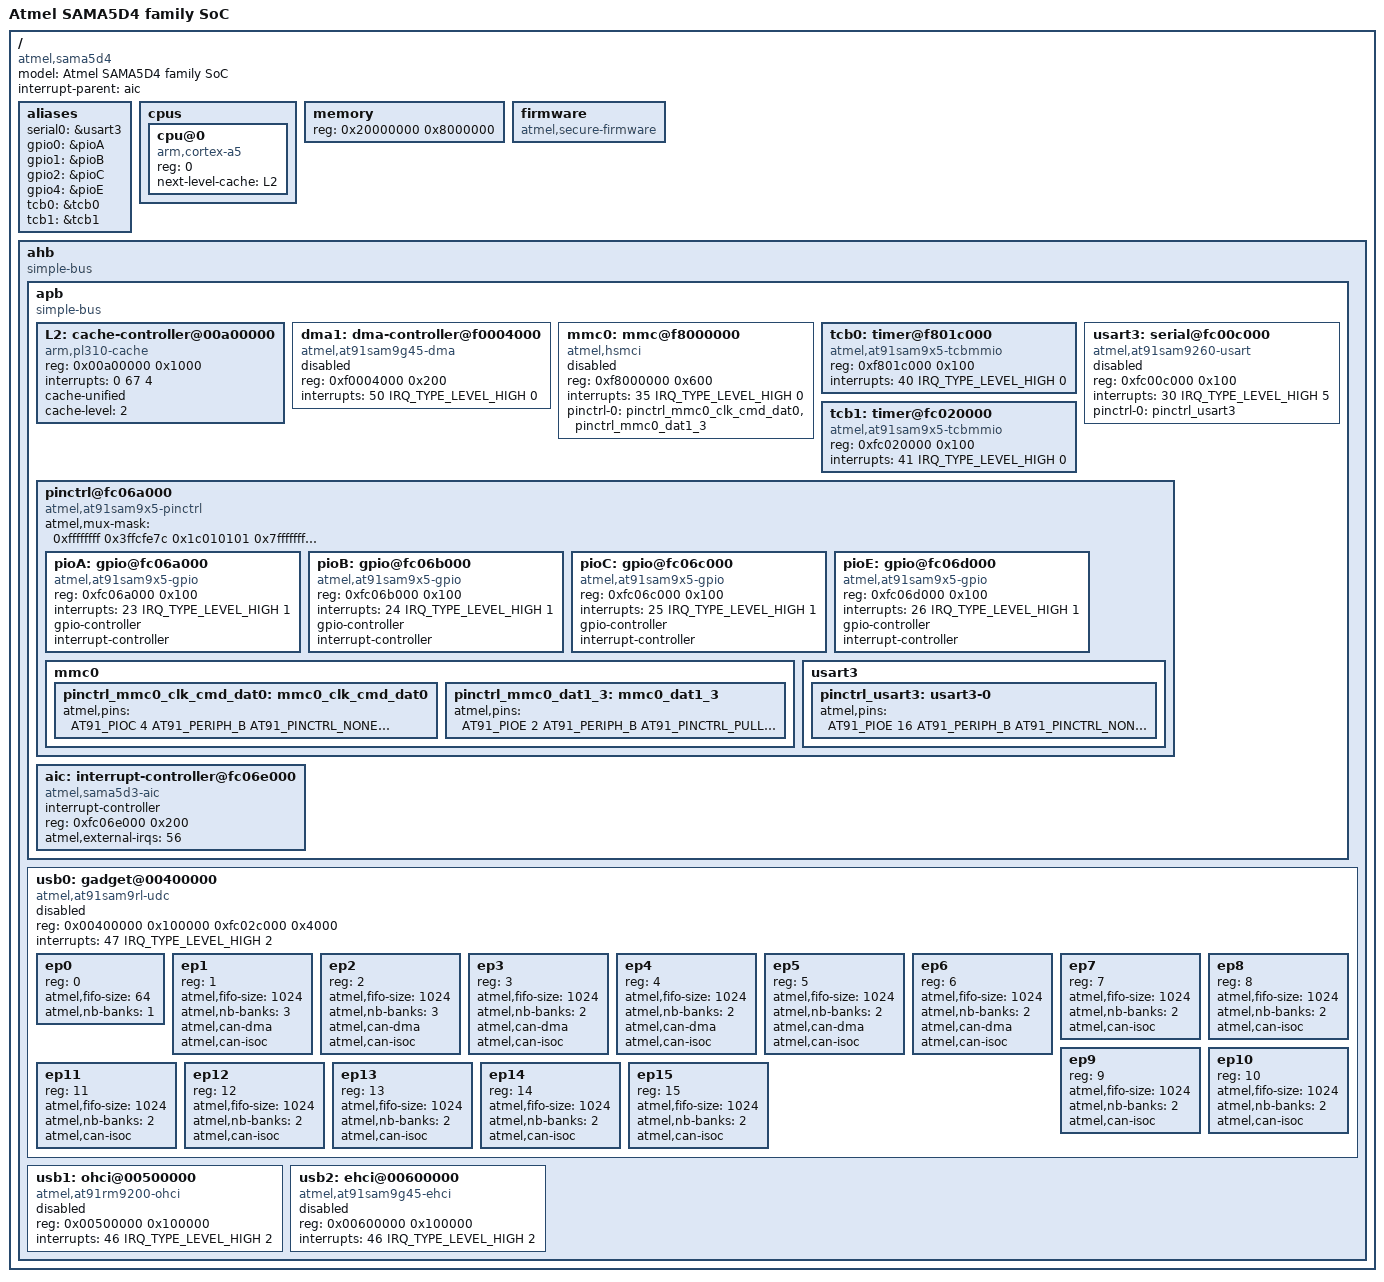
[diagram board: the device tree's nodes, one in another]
/*
 * sama5d4.dtsi - Device Tree Include file for SAMA5D4 family SoC
 *                applies to ISLERO SoC
 *
 *  Copyright (C) 2013 Atmel,
 *                2013 Nicolas Ferre <nicolas.ferre@atmel.com>
 *
 * Licensed under GPLv2 or later.
 */

#include "skeleton.dtsi"
#include <dt-bindings/dma/at91.h>
#include <dt-bindings/pinctrl/at91.h>
#include <dt-bindings/interrupt-controller/irq.h>
#include <dt-bindings/gpio/gpio.h>

/ {
	model = "Atmel SAMA5D4 family SoC";
	compatible = "atmel,sama5d4";
	interrupt-parent = <&aic>;

	aliases {
		serial0 = &usart3;
		gpio0 = &pioA;
		gpio1 = &pioB;
		gpio2 = &pioC;
		gpio4 = &pioE;
		tcb0 = &tcb0;
		tcb1 = &tcb1;
	};
	cpus {
		#address-cells = <1>;
		#size-cells = <0>;

		cpu@0 {
			compatible = "arm,cortex-a5";
			reg = <0>;
			next-level-cache = <&L2>;
		};
	};

	memory {
		reg = <0x20000000 0x8000000>;
	};

	firmware {
		compatible = "atmel,secure-firmware";
	};

	ahb {
		compatible = "simple-bus";
		#address-cells = <1>;
		#size-cells = <1>;
		ranges;

		apb {
			compatible = "simple-bus";
			#address-cells = <1>;
			#size-cells = <1>;
			ranges;

			L2: cache-controller@00a00000 {
				compatible = "arm,pl310-cache";
				reg = <0x00a00000 0x1000>;
				interrupts = <0 67 4>;
				cache-unified;
				cache-level = <2>;
				/*arm,data-latency = <1 1 1>;*/
				/*arm,tag-latency = <1 1 1>;*/
			};

			dma1: dma-controller@f0004000 {
				compatible = "atmel,at91sam9g45-dma";
				reg = <0xf0004000 0x200>;
				interrupts = <50 IRQ_TYPE_LEVEL_HIGH 0>;
				#dma-cells = <1>;
				status = "disabled";
			};

			mmc0: mmc@f8000000 {
				compatible = "atmel,hsmci";
				reg = <0xf8000000 0x600>;
				interrupts = <35 IRQ_TYPE_LEVEL_HIGH 0>;
				pinctrl-names = "default";
				pinctrl-0 = <&pinctrl_mmc0_clk_cmd_dat0 &pinctrl_mmc0_dat1_3>;
				status = "disabled";
				#address-cells = <1>;
				#size-cells = <0>;
				/*dma = <&dma1 0x10002200>; *//* cfg = ATC_FIFOCFG_HALFFIFO
								| ATC_SRC_H2SEL_HW | ATC_DST_H2SEL_HW;
								| ATC_SRC_PER(AT_DMA_ID_MCI1)
								| ATC_DST_PER(AT_DMA_ID_MCI1) */
			};

			tcb0: timer@f801c000 {
				compatible = "atmel,at91sam9x5-tcbmmio";
				reg = <0xf801c000 0x100>;
				interrupts = <40 IRQ_TYPE_LEVEL_HIGH 0>;
			};

			usart3: serial@fc00c000 {
				compatible = "atmel,at91sam9260-usart";
				reg = <0xfc00c000 0x100>;
				interrupts = <30 IRQ_TYPE_LEVEL_HIGH 5>;
				pinctrl-names = "default";
				pinctrl-0 = <&pinctrl_usart3>;
				status = "disabled";
			};

			tcb1: timer@fc020000 {
				compatible = "atmel,at91sam9x5-tcbmmio";
				reg = <0xfc020000 0x100>;
				interrupts = <41 IRQ_TYPE_LEVEL_HIGH 0>;
			};

			pinctrl@fc06a000 {
				#address-cells = <1>;
				#size-cells = <1>;
				compatible = "atmel,at91sam9x5-pinctrl", "atmel,at91rm9200-pinctrl", "simple-bus";
				ranges = <0xfc06a000 0xfc06a000 0x4000>;
				/* WARNING: revisit as pin spec has changed */
				atmel,mux-mask = <
					/*   A          B          C  */
					0xffffffff 0x3ffcfe7c 0x1c010101	/* pioA */
					0x7fffffff 0xfffccc3a 0x3f00cc3a	/* pioB */
					0xffffffff 0x3ff83fff 0xff00ffff	/* pioC */
					0x00000000 0x00000000 0x00000000	/* pioD */
					0xffffffff 0x7fffffff 0x76fff1bf	/* pioE */
					>;

				pioA: gpio@fc06a000 {
					compatible = "atmel,at91sam9x5-gpio", "atmel,at91rm9200-gpio";
					reg = <0xfc06a000 0x100>;
					interrupts = <23 IRQ_TYPE_LEVEL_HIGH 1>;
					#gpio-cells = <2>;
					gpio-controller;
					interrupt-controller;
					#interrupt-cells = <2>;
				};

				pioB: gpio@fc06b000 {
					compatible = "atmel,at91sam9x5-gpio", "atmel,at91rm9200-gpio";
					reg = <0xfc06b000 0x100>;
					interrupts = <24 IRQ_TYPE_LEVEL_HIGH 1>;
					#gpio-cells = <2>;
					gpio-controller;
					interrupt-controller;
					#interrupt-cells = <2>;
				};

				pioC: gpio@fc06c000 {
					compatible = "atmel,at91sam9x5-gpio", "atmel,at91rm9200-gpio";
					reg = <0xfc06c000 0x100>;
					interrupts = <25 IRQ_TYPE_LEVEL_HIGH 1>;
					#gpio-cells = <2>;
					gpio-controller;
					interrupt-controller;
					#interrupt-cells = <2>;
				};

				pioE: gpio@fc06d000 {
					compatible = "atmel,at91sam9x5-gpio", "atmel,at91rm9200-gpio";
					reg = <0xfc06d000 0x100>;
					interrupts = <26 IRQ_TYPE_LEVEL_HIGH 1>;
					#gpio-cells = <2>;
					gpio-controller;
					interrupt-controller;
					#interrupt-cells = <2>;
				};

				/* pinctrl pin settings */

				mmc0 {
					pinctrl_mmc0_clk_cmd_dat0: mmc0_clk_cmd_dat0 {
						atmel,pins =
							<AT91_PIOC 4 AT91_PERIPH_B AT91_PINCTRL_NONE	/* MCI0_CK */
							 AT91_PIOE 0 AT91_PERIPH_B AT91_PINCTRL_PULL_UP	/* MCI0_CDB */
							 AT91_PIOE 1 AT91_PERIPH_B AT91_PINCTRL_PULL_UP	/* MCI0_DB0 */
							>;
					};
					pinctrl_mmc0_dat1_3: mmc0_dat1_3 {
						atmel,pins =
							<AT91_PIOE 2 AT91_PERIPH_B AT91_PINCTRL_PULL_UP	/* MCI0_DB1 */
							 AT91_PIOE 3 AT91_PERIPH_B AT91_PINCTRL_PULL_UP	/* MCI0_DB2 */
							 AT91_PIOE 4 AT91_PERIPH_B AT91_PINCTRL_PULL_UP	/* MCI0_DB3 */
							>;
					};
				};
				usart3 {
					pinctrl_usart3: usart3-0 {
						atmel,pins =
							<AT91_PIOE 16 AT91_PERIPH_B AT91_PINCTRL_NONE		/* RXD */
							 AT91_PIOE 17 AT91_PERIPH_B AT91_PINCTRL_PULL_UP	/* TXD */
							>;
					};
				};
			};

			aic: interrupt-controller@fc06e000 {
				#interrupt-cells = <3>;
				compatible = "atmel,sama5d3-aic";
				interrupt-controller;
				reg = <0xfc06e000 0x200>;
				atmel,external-irqs = <56>;
			};
		};

		usb0: gadget@00400000 {
			#address-cells = <1>;
			#size-cells = <0>;
			compatible = "atmel,at91sam9rl-udc";
			reg = <0x00400000 0x100000
			       0xfc02c000 0x4000>;
			interrupts = <47 IRQ_TYPE_LEVEL_HIGH 2>;
			status = "disabled";

			ep0 {
				reg = <0>;
				atmel,fifo-size = <64>;
				atmel,nb-banks = <1>;
			};

			ep1 {
				reg = <1>;
				atmel,fifo-size = <1024>;
				atmel,nb-banks = <3>;
				atmel,can-dma;
				atmel,can-isoc;
			};

			ep2 {
				reg = <2>;
				atmel,fifo-size = <1024>;
				atmel,nb-banks = <3>;
				atmel,can-dma;
				atmel,can-isoc;
			};

			ep3 {
				reg = <3>;
				atmel,fifo-size = <1024>;
				atmel,nb-banks = <2>;
				atmel,can-dma;
				atmel,can-isoc;
			};

			ep4 {
				reg = <4>;
				atmel,fifo-size = <1024>;
				atmel,nb-banks = <2>;
				atmel,can-dma;
				atmel,can-isoc;
			};

			ep5 {
				reg = <5>;
				atmel,fifo-size = <1024>;
				atmel,nb-banks = <2>;
				atmel,can-dma;
				atmel,can-isoc;
			};

			ep6 {
				reg = <6>;
				atmel,fifo-size = <1024>;
				atmel,nb-banks = <2>;
				atmel,can-dma;
				atmel,can-isoc;
			};

			ep7 {
				reg = <7>;
				atmel,fifo-size = <1024>;
				atmel,nb-banks = <2>;
				atmel,can-isoc;
			};

			ep8 {
				reg = <8>;
				atmel,fifo-size = <1024>;
				atmel,nb-banks = <2>;
				atmel,can-isoc;
			};

			ep9 {
				reg = <9>;
				atmel,fifo-size = <1024>;
				atmel,nb-banks = <2>;
				atmel,can-isoc;
			};

			ep10 {
				reg = <10>;
				atmel,fifo-size = <1024>;
				atmel,nb-banks = <2>;
				atmel,can-isoc;
			};

			ep11 {
				reg = <11>;
				atmel,fifo-size = <1024>;
				atmel,nb-banks = <2>;
				atmel,can-isoc;
			};

			ep12 {
				reg = <12>;
				atmel,fifo-size = <1024>;
				atmel,nb-banks = <2>;
				atmel,can-isoc;
			};

			ep13 {
				reg = <13>;
				atmel,fifo-size = <1024>;
				atmel,nb-banks = <2>;
				atmel,can-isoc;
			};

			ep14 {
				reg = <14>;
				atmel,fifo-size = <1024>;
				atmel,nb-banks = <2>;
				atmel,can-isoc;
			};

			ep15 {
				reg = <15>;
				atmel,fifo-size = <1024>;
				atmel,nb-banks = <2>;
				atmel,can-isoc;
			};
		};

		usb1: ohci@00500000 {
			compatible = "atmel,at91rm9200-ohci", "usb-ohci";
			reg = <0x00500000 0x100000>;
			interrupts = <46 IRQ_TYPE_LEVEL_HIGH 2>;
			status = "disabled";
		};

		usb2: ehci@00600000 {
			compatible = "atmel,at91sam9g45-ehci", "usb-ehci";
			reg = <0x00600000 0x100000>;
			interrupts = <46 IRQ_TYPE_LEVEL_HIGH 2>;
			status = "disabled";
		};
	};
};
